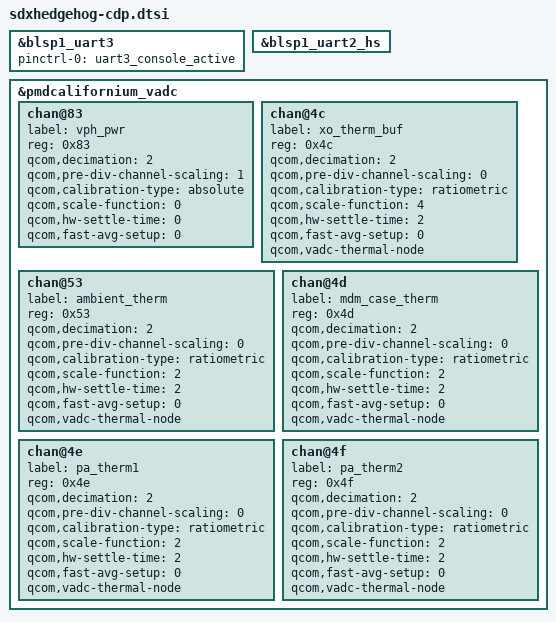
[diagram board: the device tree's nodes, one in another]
/* Copyright (c) 2016, The Linux Foundation. All rights reserved.
 *
 * This program is free software; you can redistribute it and/or modify
 * it under the terms of the GNU General Public License version 2 and
 * only version 2 as published by the Free Software Foundation.
 *
 * This program is distributed in the hope that it will be useful,
 * but WITHOUT ANY WARRANTY; without even the implied warranty of
 * MERCHANTABILITY or FITNESS FOR A PARTICULAR PURPOSE.  See the
 * GNU General Public License for more details.
 */

#include <dt-bindings/interrupt-controller/irq.h>
#include "sdxhedgehog.dtsi"
#include "sdxhedgehog-pinctrl.dtsi"

&blsp1_uart3 {
	status = "ok";
	pinctrl-names = "default";
	pinctrl-0 = <&uart3_console_active>;
};

&blsp1_uart2_hs {
	status = "ok";
};

&pmdcalifornium_vadc {
	chan@83 {
		label = "vph_pwr";
		reg = <0x83>;
		qcom,decimation = <2>;
		qcom,pre-div-channel-scaling = <1>;
		qcom,calibration-type = "absolute";
		qcom,scale-function = <0>;
		qcom,hw-settle-time = <0>;
		qcom,fast-avg-setup = <0>;
	};

	chan@4c {
		label = "xo_therm_buf";
		reg = <0x4c>;
		qcom,decimation = <2>;
		qcom,pre-div-channel-scaling = <0>;
		qcom,calibration-type = "ratiometric";
		qcom,scale-function = <4>;
		qcom,hw-settle-time = <2>;
		qcom,fast-avg-setup = <0>;
		qcom,vadc-thermal-node;
	};

	chan@53 {
		label = "ambient_therm";
		reg = <0x53>;
		qcom,decimation = <2>;
		qcom,pre-div-channel-scaling = <0>;
		qcom,calibration-type = "ratiometric";
		qcom,scale-function = <2>;
		qcom,hw-settle-time = <2>;
		qcom,fast-avg-setup = <0>;
		qcom,vadc-thermal-node;
	};

	chan@4d {
		label = "mdm_case_therm";
		reg = <0x4d>;
		qcom,decimation = <2>;
		qcom,pre-div-channel-scaling = <0>;
		qcom,calibration-type = "ratiometric";
		qcom,scale-function = <2>;
		qcom,hw-settle-time = <2>;
		qcom,fast-avg-setup = <0>;
		qcom,vadc-thermal-node;
	};

	chan@4e {
		label = "pa_therm1";
		reg = <0x4e>;
		qcom,decimation = <2>;
		qcom,pre-div-channel-scaling = <0>;
		qcom,calibration-type = "ratiometric";
		qcom,scale-function = <2>;
		qcom,hw-settle-time = <2>;
		qcom,fast-avg-setup = <0>;
		qcom,vadc-thermal-node;
	};

	chan@4f {
		label = "pa_therm2";
		reg = <0x4f>;
		qcom,decimation = <2>;
		qcom,pre-div-channel-scaling = <0>;
		qcom,calibration-type = "ratiometric";
		qcom,scale-function = <2>;
		qcom,hw-settle-time = <2>;
		qcom,fast-avg-setup = <0>;
		qcom,vadc-thermal-node;
	};
};
